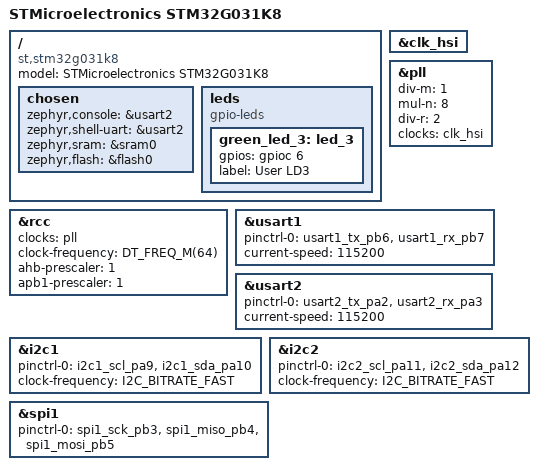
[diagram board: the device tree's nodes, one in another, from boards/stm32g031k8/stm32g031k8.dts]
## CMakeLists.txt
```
cmake_minimum_required(VERSION 3.20.0)

list(APPEND BOARD_ROOT ${CMAKE_CURRENT_SOURCE_DIR})
find_package(Zephyr REQUIRED)
project(my_zephyr_app)

target_sources(app PRIVATE src/main.cpp)
add_subdirectory(drivers)
include_directories(include/led_sensor)
```

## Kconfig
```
source "Kconfig.zephyr"

config APP_HEARTBEAT_PERIOD_MS 
    int "Fade duration (ms)"
    range 100 2000
    default 500

menuconfig LED_SUBSYSTEM
    bool "LED Subsystem"
    default y

if LED_SUBSYSTEM
    choice 
        prompt "LED blink sleep time"
        default BLINK_SLEEP_1000MS

    config BLINK_SLEEP_250MS
        bool "Fast (250ms)"

    config BLINK_SLEEP_1000MS
        bool "Medium (1s)"

    config BLINK_SLEEP_2000MS
        bool "Slow (2s)"
    endchoice

    config LED_BLINK_SLEEP_TIME_MS
        int #
        default 250  if BLINK_SLEEP_250MS
        default 1000 if BLINK_SLEEP_1000MS
        default 2000 if BLINK_SLEEP_2000MS
        default 0
 
    menuconfig LED_ADVANCED_SETTINGS
        bool "Advanced LED settings"
        default n

    if LED_ADVANCED_SETTINGS       
        config LED_BRIGHTNESS
            int "LED brightness (0-100)"
            range 0 100
            default 100

        config LED_FADE_DURATION_MS
            int "Fade duration (ms)"
            range 0 5000
            default 500

        menu "Expert settings"
            config LED_DEBUGGING
                bool "Enable LED debugging"
                default n
            config CUSTOM_BLINK
                bool "Custom blink pattern"
                default n
        endmenu
    endif
endif
```

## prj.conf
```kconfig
CONFIG_GPIO=y
CONFIG_LED_SENSOR=y
CONFIG_SHELL=y
CONFIG_SHELL_CMDS=y
CONFIG_SHELL_TAB=y
CONFIG_SHELL_TAB_AUTOCOMPLETION=y
CONFIG_SHELL_HISTORY=y
CONFIG_SHELL_BACKEND_SERIAL=y
```

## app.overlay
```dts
/ {
	led_sensor0: led_sensor {
		compatible = "led,sensor";
		status = "okay";
		led-gpios = <&gpio0 0 GPIO_ACTIVE_HIGH>;
	};
};
```

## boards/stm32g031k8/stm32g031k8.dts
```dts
/*
 * Copyright (c) 2022 Joylab AG <team@joylab.ch>
 *
 * SPDX-License-Identifier: Apache-2.0
 */

/dts-v1/;
#include <st/g0/stm32g031X8.dtsi>
#include <st/g0/stm32g031k(4-6-8)tx-pinctrl.dtsi>

/ {
	model = "STMicroelectronics STM32G031K8";
	compatible = "st,stm32g031k8";

	chosen {
		zephyr,console = &usart2;
		zephyr,shell-uart = &usart2;
		zephyr,sram = &sram0;
		zephyr,flash = &flash0;
	};

	leds: leds {
		compatible = "gpio-leds";

		green_led_3: led_3 {
			gpios = <&gpioc 6 GPIO_ACTIVE_HIGH>;
			label = "User LD3";
		};
	};

};

&clk_hsi {
	status = "okay";
};

&pll {
	div-m = <1>;
	mul-n = <8>;
	div-r = <2>;
	clocks = <&clk_hsi>;
	status = "okay";
};

&rcc {
	clocks = <&pll>;
	clock-frequency = <DT_FREQ_M(64)>;
	ahb-prescaler = <1>;
	apb1-prescaler = <1>;
};

&usart1 {
	pinctrl-0 = <&usart1_tx_pb6 &usart1_rx_pb7>;
	pinctrl-names = "default";
	current-speed = <115200>;
};

&usart2 {
	pinctrl-0 = <&usart2_tx_pa2 &usart2_rx_pa3>;
	pinctrl-names = "default";
	current-speed = <115200>;
	status = "okay";
};

&i2c1 {
	pinctrl-0 = <&i2c1_scl_pa9 &i2c1_sda_pa10>;
	pinctrl-names = "default";
	clock-frequency = <I2C_BITRATE_FAST>;
	status = "okay";
};

&i2c2 {
	pinctrl-0 = <&i2c2_scl_pa11 &i2c2_sda_pa12>;
	pinctrl-names = "default";
	clock-frequency = <I2C_BITRATE_FAST>;
	status = "okay";
};

&spi1 {
	pinctrl-0 = <&spi1_sck_pb3 &spi1_miso_pb4 &spi1_mosi_pb5>;
	pinctrl-names = "default";
	status = "okay";
};
```

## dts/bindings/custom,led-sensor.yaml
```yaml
description: Custom Led Sensor binding
compatible: "custom,led-sensor"
include: base.yaml

properties: 
  led-gpios:
    type: phandle-array
    required: true
```

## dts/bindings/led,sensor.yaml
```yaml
description: Custom Led Sensor binding
compatible: "led,sensor"
include: base.yaml

properties: 
  led-gpios:
    type: phandle-array
    required: true
```

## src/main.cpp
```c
#include <zephyr/device.h>
#include <zephyr/devicetree.h>
#include <zephyr/drivers/sensor.h>
#include <zephyr/kernel.h>
#include <zephyr/shell/shell.h>

static const struct device *get_led_sensor_device(const struct shell *sh) {
  const struct device *const dev = DEVICE_DT_GET_ANY(led_sensor);

  if (dev == NULL) {
    /* No such node, or the node does not have status "okay". */
    shell_print(sh, "\nError: no device found.\n");
    return NULL;
  }

  if (!device_is_ready(dev)) {
    shell_print(sh,
                "\nError: Device \"%s\" is not ready; "
                "check the driver initialization logs for errors.\n",
                dev->name);
    return NULL;
  }

  shell_print(sh, "Found device \"%s\", getting sensor data\n", dev->name);
  return dev;
}

static int cmd_fetch(const struct shell *sh, size_t argc, char **argv) {
  ARG_UNUSED(argc);
  ARG_UNUSED(argv);
  const struct device *dev = get_led_sensor_device(sh);

  int ret = sensor_sample_fetch(dev);

  if (ret < 0) {
    shell_error(sh, "Fetching new Data from \"%s\" failed");
    return ret;
  }

  shell_print(sh, "Fetching new Data successful (LED on)");

  return 0;
}

static int cmd_read(const struct shell *sh, size_t argc, char **argv) {
  ARG_UNUSED(argc);
  ARG_UNUSED(argv);
  const struct device *dev = get_led_sensor_device(sh);

  struct sensor_value value;

  int ret = sensor_channel_get(dev, SENSOR_CHAN_POWER, &value);

  if (ret < 0) {
    shell_error(sh, "Fetching new Data from \"%s\" failed");
    return ret;
  }

  shell_print(sh, "Reading new Data successful (LED off)");

  return 0;
}

static int cmd_info(const struct shell *sh, size_t argc, char **argv) {
  ARG_UNUSED(argc);
  ARG_UNUSED(argv);
  const struct device *dev = get_led_sensor_device(sh);

  struct sensor_value value;

  shell_print(sh, "Device Name: %s", dev->name);
  shell_print(sh, "Device State: %s",
              device_is_ready(dev) ? "Ready" : "Not Ready");

  return 0;
}

SHELL_STATIC_SUBCMD_SET_CREATE(
    sub_sensor, SHELL_CMD(fetch, NULL, "Fetch new Sensor Data", cmd_fetch),
    SHELL_CMD(read, NULL, "Read new Sensor Data", cmd_read),
    SHELL_CMD(info, NULL, "Get Device Name and State", cmd_info),
    SHELL_SUBCMD_SET_END);

SHELL_CMD_REGISTER(led_sensor, &sub_sensor, "LED Sensor Commands", NULL);

int main(void) { return 0; }
```
